AUTOSAR XML (schema 4-2-2)
package /Components
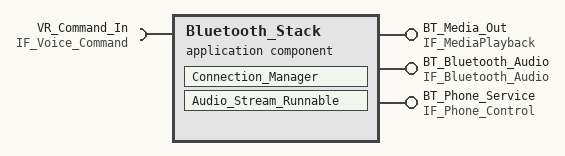
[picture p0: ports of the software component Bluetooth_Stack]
  application sw component type Bluetooth_Stack
    provide port BT_Media_Out: provided-interface=IF_MediaPlayback
    provide port BT_Bluetooth_Audio: provided-interface=IF_Bluetooth_Audio
    provide port BT_Phone_Service: provided-interface=IF_Phone_Control
    require port VR_Command_In: required-interface=IF_Voice_Command
    behavior Bluetooth_Stack_Behavior
      asynchronous server call returns event BT_Async_Call_Return: start-on-event=Read_CAN_Runnable, event-source=PhoneCallResult
      data received event BT_Data_Received: start-on-event=Read_CAN_Runnable
      runnable Connection_Manager: minimum-start-interval=100, symbol=Bluetooth_Stack_Connection_Manager
        data-send-points:
          access PhoneEvent_Access: accessed-variable=BT_Phone_Service.PhoneEvent
        async call Async_Dial_Call: operation=VR_Command_In.Dial, timeout=2000
      runnable Audio_Stream_Runnable: minimum-start-interval=20, can-be-invoked-concurrently=true, symbol=Bluetooth_Stack_Audio_Stream_Runnable
        data-send-points:
          access Audio_Out_Access: accessed-variable=BT_Media_Out.AudioChunk
        async call Async_StartStream_Call: operation=VR_Command_In.StartStream, timeout=500
